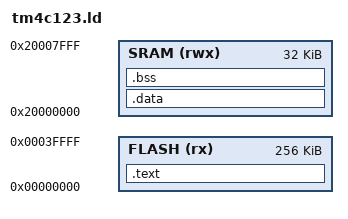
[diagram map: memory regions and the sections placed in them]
/*
 * Linker script for TM4C123GH6PM
 */

MEMORY
{
  FLASH (rx) : ORIGIN = 0x00000000, LENGTH = 256K
  SRAM (rwx) : ORIGIN = 0x20000000, LENGTH = 32K
}

SECTIONS
{
  .text :
  {
    KEEP(*(.isr_vector))
    *(.text*)
    *(.rodata*)
  } > FLASH

  .data : AT (ADDR(.text) + SIZEOF(.text))
  {
    *(.data*)
  } > SRAM

  .bss :
  {
    *(.bss*)
  } > SRAM
}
